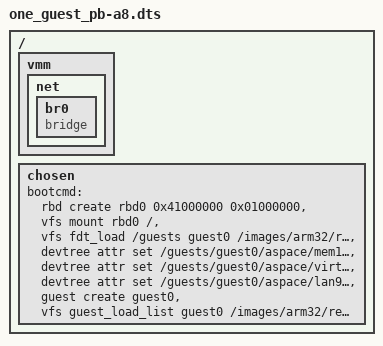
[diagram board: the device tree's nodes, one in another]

/dts-v1/;

/include/ "smdkc210.dtsi"

/ {
	vmm {
		net {
			br0 {
				device_type = "netswitch";
				compatible = "bridge";
			};
		};
	};

	chosen {
		bootcmd = /* Create rbd0 device */
			  "rbd create rbd0 0x41000000 0x01000000",

			  /* Mount rbd0 device */
			  "vfs mount rbd0 /",

			  /* Load guest0 device tree from file */
			  "vfs fdt_load /guests guest0 /images/arm32/realview-pb-a8.dtb",

			  /* Update guest0/mem1 region size */
			  "devtree attr set /guests/guest0/aspace/mem1 physical_size physsize 0x06000000",

			  /* Connect guest0/virtio-net0 netport to br0 */
			  "devtree attr set /guests/guest0/aspace/virtio-net0 switch string br0",

			  /* Connect guest0/lan9118 netport to br0 */
			  "devtree attr set /guests/guest0/aspace/lan9118 switch string br0",

			  /* Create guest0 */
			  "guest create guest0",

			  /* Load guest0 images */
			  "vfs guest_load_list guest0 /images/arm32/realview-pb-a8/nor_flash.list";
	};
};
